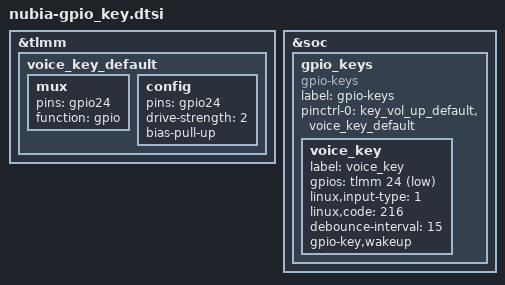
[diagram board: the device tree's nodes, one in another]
&tlmm {
	voice_key_default: voice_key_default {
		mux {
			pins = "gpio24";
			function = "gpio";
		};

		config {
			pins = "gpio24";
			drive-strength = <2>;
			bias-pull-up;
		};
	};
};

&soc {
	gpio_keys {
	       compatible = "gpio-keys";
               label = "gpio-keys";

		pinctrl-0 = <&key_vol_up_default &voice_key_default>;
		voice_key {
			label = "voice_key";
			gpios = <&tlmm 24 GPIO_ACTIVE_LOW>;
			linux,input-type = <1>;
			linux,code = <216>;
			debounce-interval = <15>;
			gpio-key,wakeup;
		};
	};
};
